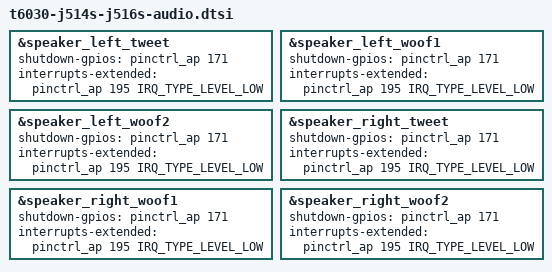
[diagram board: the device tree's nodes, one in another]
// SPDX-License-Identifier: GPL-2.0+ OR MIT
/* Speaker amplifier wiring shared by the 14- and 16-inch M3 Pro. */

&speaker_left_tweet {
	shutdown-gpios = <&pinctrl_ap 171 GPIO_ACTIVE_HIGH>;
	interrupts-extended = <&pinctrl_ap 195 IRQ_TYPE_LEVEL_LOW>;
};

&speaker_left_woof1 {
	shutdown-gpios = <&pinctrl_ap 171 GPIO_ACTIVE_HIGH>;
	interrupts-extended = <&pinctrl_ap 195 IRQ_TYPE_LEVEL_LOW>;
};

&speaker_left_woof2 {
	shutdown-gpios = <&pinctrl_ap 171 GPIO_ACTIVE_HIGH>;
	interrupts-extended = <&pinctrl_ap 195 IRQ_TYPE_LEVEL_LOW>;
};

&speaker_right_tweet {
	shutdown-gpios = <&pinctrl_ap 171 GPIO_ACTIVE_HIGH>;
	interrupts-extended = <&pinctrl_ap 195 IRQ_TYPE_LEVEL_LOW>;
};

&speaker_right_woof1 {
	shutdown-gpios = <&pinctrl_ap 171 GPIO_ACTIVE_HIGH>;
	interrupts-extended = <&pinctrl_ap 195 IRQ_TYPE_LEVEL_LOW>;
};

&speaker_right_woof2 {
	shutdown-gpios = <&pinctrl_ap 171 GPIO_ACTIVE_HIGH>;
	interrupts-extended = <&pinctrl_ap 195 IRQ_TYPE_LEVEL_LOW>;
};
